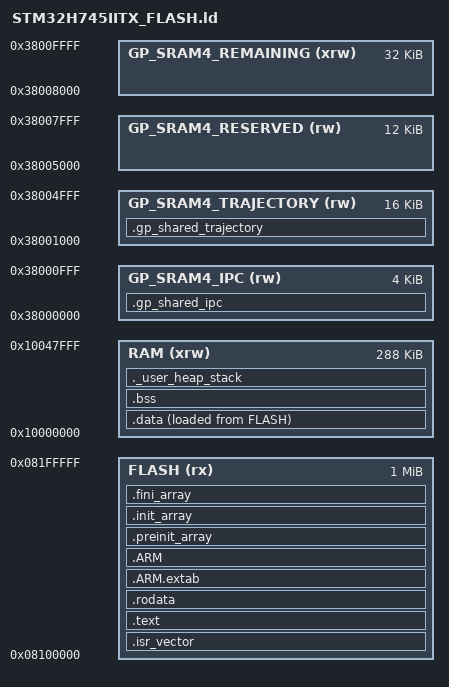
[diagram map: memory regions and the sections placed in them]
/*
******************************************************************************
**
**  File        : LinkerScript.ld
**
**  Author      : STM32CubeIDE
**
**  Abstract    : Linker script for STM32H7 series
**                1024Kbytes FLASH and 288Kbytes RAM
**
**                Set heap size, stack size and stack location according
**                to application requirements.
**
**                Set memory bank area and size if external memory is used.
**
**  Target      : STMicroelectronics STM32
**
**  Distribution: The file is distributed as is, without any warranty
**                of any kind.
**
*****************************************************************************
** @attention
**
** Copyright (c) 2026 STMicroelectronics.
** All rights reserved.
**
** This software is licensed under terms that can be found in the LICENSE file
** in the root directory of this software component.
** If no LICENSE file comes with this software, it is provided AS-IS.
**
****************************************************************************
*/

/* Entry Point */
ENTRY(Reset_Handler)

/* Highest address of the user mode stack */
_estack = ORIGIN(RAM) + LENGTH(RAM); /* end of RAM */
/* Generate a link error if heap and stack don't fit into RAM */
_Min_Heap_Size = 0x200;      /* required amount of heap  */
_Min_Stack_Size = 0x400; /* required amount of stack */

/* Specify the memory areas */
MEMORY
{
FLASH (rx)     : ORIGIN = 0x08100000, LENGTH = 1024K
RAM (xrw)      : ORIGIN = 0x10000000, LENGTH = 288K
  /* Physical SRAM4 shared by CM7 and CM4; disjoint reserved slots. */
  GP_SRAM4_IPC        (rw)  : ORIGIN = 0x38000000, LENGTH = 4K
  GP_SRAM4_TRAJECTORY (rw)  : ORIGIN = 0x38001000, LENGTH = 16K
  GP_SRAM4_RESERVED   (rw)  : ORIGIN = 0x38005000, LENGTH = 12K
  GP_SRAM4_REMAINING  (xrw) : ORIGIN = 0x38008000, LENGTH = 32K
}

/* Define output sections */
SECTIONS
{
  /* The startup code goes first into FLASH */
  .isr_vector :
  {
    . = ALIGN(4);
    KEEP(*(.isr_vector)) /* Startup code */
    . = ALIGN(4);
  } >FLASH

  /* The program code and other data goes into FLASH */
  .text :
  {
    . = ALIGN(4);
    *(.text)           /* .text sections (code) */
    *(.text*)          /* .text* sections (code) */
    *(.glue_7)         /* glue arm to thumb code */
    *(.glue_7t)        /* glue thumb to arm code */
    *(.eh_frame)

    KEEP (*(.init))
    KEEP (*(.fini))

    . = ALIGN(4);
    _etext = .;        /* define a global symbols at end of code */
  } >FLASH

  /* Constant data goes into FLASH */
  .rodata :
  {
    . = ALIGN(4);
    *(.rodata)         /* .rodata sections (constants, strings, etc.) */
    *(.rodata*)        /* .rodata* sections (constants, strings, etc.) */
    . = ALIGN(4);
  } >FLASH

  .ARM.extab (READONLY) : /* The READONLY keyword is only supported in GCC11 and later, remove it if using GCC10 or earlier. */
  {
    *(.ARM.extab* .gnu.linkonce.armextab.*)
  } >FLASH
  .ARM (READONLY) : /* The READONLY keyword is only supported in GCC11 and later, remove it if using GCC10 or earlier. */
  {
    __exidx_start = .;
    *(.ARM.exidx*)
    __exidx_end = .;
  } >FLASH

  .preinit_array (READONLY) : /* The READONLY keyword is only supported in GCC11 and later, remove it if using GCC10 or earlier. */
  {
    PROVIDE_HIDDEN (__preinit_array_start = .);
    KEEP (*(.preinit_array*))
    PROVIDE_HIDDEN (__preinit_array_end = .);
  } >FLASH
  .init_array (READONLY) : /* The READONLY keyword is only supported in GCC11 and later, remove it if using GCC10 or earlier. */
  {
    PROVIDE_HIDDEN (__init_array_start = .);
    KEEP (*(SORT(.init_array.*)))
    KEEP (*(.init_array*))
    PROVIDE_HIDDEN (__init_array_end = .);
  } >FLASH
  .fini_array (READONLY) : /* The READONLY keyword is only supported in GCC11 and later, remove it if using GCC10 or earlier. */
  {
    PROVIDE_HIDDEN (__fini_array_start = .);
    KEEP (*(SORT(.fini_array.*)))
    KEEP (*(.fini_array*))
    PROVIDE_HIDDEN (__fini_array_end = .);
  } >FLASH

  /* used by the startup to initialize data */
  _sidata = LOADADDR(.data);

  /* Initialized data sections goes into RAM, load LMA copy after code */
  .data :
  {
    . = ALIGN(4);
    _sdata = .;        /* create a global symbol at data start */
    *(.data)           /* .data sections */
    *(.data*)          /* .data* sections */
    *(.RamFunc)        /* .RamFunc sections */
    *(.RamFunc*)       /* .RamFunc* sections */

    . = ALIGN(4);
    _edata = .;        /* define a global symbol at data end */
  } >RAM AT> FLASH


  /* Uninitialized data section */
  . = ALIGN(4);
  .bss :
  {
    /* This is used by the startup in order to initialize the .bss section */
    _sbss = .;         /* define a global symbol at bss start */
    __bss_start__ = _sbss;
    *(.bss)
    *(.bss*)
    *(COMMON)

    . = ALIGN(4);
    _ebss = .;         /* define a global symbol at bss end */
    __bss_end__ = _ebss;
  } >RAM

  /* Stage 2C: shared SRAM4 objects, NOT part of either core's .bss clear.
   * These sections must hold only uninitialized objects. Cross-core
   * initialization and MPU cache policy are separate future gates. */
  .gp_shared_ipc (NOLOAD) :
  {
    . = ALIGN(32);
    __gp_shared_ipc_start__ = .;
    KEEP(*(.gp_shared_ipc))
    KEEP(*(.gp_shared_ipc.*))
    . = ALIGN(32);
    __gp_shared_ipc_end__ = .;
  } >GP_SRAM4_IPC

  .gp_shared_trajectory (NOLOAD) :
  {
    . = ALIGN(32);
    __gp_shared_trajectory_start__ = .;
    KEEP(*(.gp_shared_trajectory))
    KEEP(*(.gp_shared_trajectory.*))
    . = ALIGN(32);
    __gp_shared_trajectory_end__ = .;
  } >GP_SRAM4_TRAJECTORY

  ASSERT(ADDR(.gp_shared_ipc) == ORIGIN(GP_SRAM4_IPC),
         "Shared IPC base does not match STM32H745 SRAM4 contract")
  ASSERT(ADDR(.gp_shared_trajectory) == ORIGIN(GP_SRAM4_TRAJECTORY),
         "Shared trajectory base does not match STM32H745 SRAM4 contract")
  ASSERT(SIZEOF(.gp_shared_ipc) <= LENGTH(GP_SRAM4_IPC),
         "Shared IPC exceeds 4 KiB")
  ASSERT(SIZEOF(.gp_shared_trajectory) <= LENGTH(GP_SRAM4_TRAJECTORY),
         "Shared trajectory exceeds 16 KiB")

  /* User_heap_stack section, used to check that there is enough RAM left */
  ._user_heap_stack :
  {
    . = ALIGN(8);
    PROVIDE ( end = . );
    PROVIDE ( _end = . );
    . = . + _Min_Heap_Size;
    . = . + _Min_Stack_Size;
    . = ALIGN(8);
  } >RAM



  /* Remove information from the standard libraries */
  /DISCARD/ :
  {
    libc.a ( * )
    libm.a ( * )
    libgcc.a ( * )
  }

  .ARM.attributes 0 : { *(.ARM.attributes) }
}


